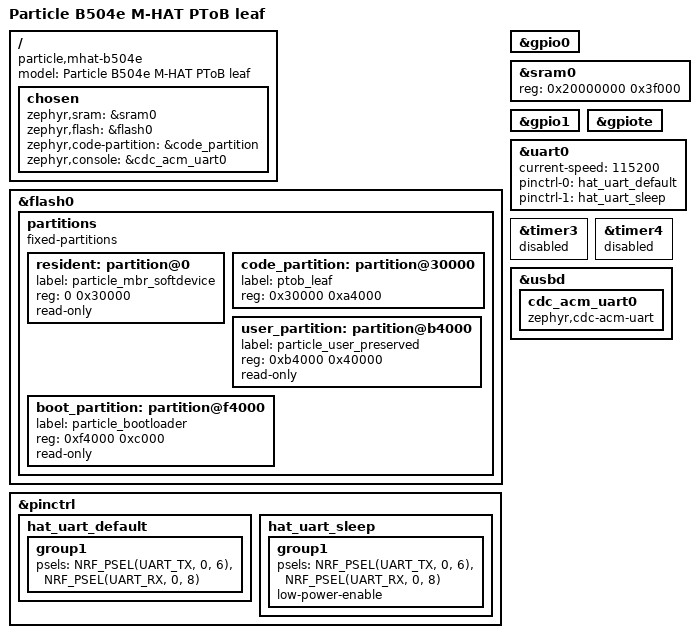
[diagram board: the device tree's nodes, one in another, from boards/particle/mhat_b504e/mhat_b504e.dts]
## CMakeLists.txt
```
# Copyright (c) 2026 Jonathan Yantis. SPDX-License-Identifier: MIT
cmake_minimum_required(VERSION 3.20.0)
list(APPEND BOARD_ROOT ${CMAKE_CURRENT_SOURCE_DIR})
find_package(Zephyr REQUIRED HINTS $ENV{ZEPHYR_BASE})
project(ptob_mhat VERSION 0.5.5)
zephyr_linker_sources(ROM_START SORT_KEY zzz ${CMAKE_CURRENT_SOURCE_DIR}/module_reserve.ld)
set(T096 ${CMAKE_CURRENT_SOURCE_DIR}/../t096)
if(NOT EXISTS "${MHAT_PRIVATE_HEADER}")
 message(FATAL_ERROR "Use tools/build.py with private exact-device enrollment")
endif()
configure_file(${MHAT_PRIVATE_HEADER} ${CMAKE_CURRENT_BINARY_DIR}/mhat_private.h COPYONLY)
target_include_directories(app PRIVATE ${CMAKE_CURRENT_SOURCE_DIR}/include ${CMAKE_CURRENT_BINARY_DIR} ${T096}/include ${T096}/protocol
 ${ZEPHYR_BASE}/subsys/bluetooth/controller/ll_sw/nordic/hal/nrf5/radio)
target_compile_definitions(app PRIVATE R2_RC_PROFILE=1 R2_SWITCHABLE_FIELD=1 R2_TZ_WIRE=1
 R2_USB_SOURCE_STREAM=1 R2_NATIVE_BLE=1)
set_source_files_properties(${T096}/src/rc_dynamic_service.c PROPERTIES COMPILE_DEFINITIONS "R2_DYNAMIC_BACKEND=1;R2_RC_DYNAMIC=1")
target_sources(app PRIVATE src/main.c src/mesh.c src/clock_adapter.c src/pps.c src/support.c src/gm_control.c
 ${T096}/src/core.c ${T096}/src/rc_dynamic_service.c ${T096}/src/rc_boundary.c ${T096}/src/rc_slots.c
 ${T096}/src/rc_unicast.c ${T096}/src/radio_capture.c ${T096}/src/radio_audit.c
 ${T096}/src/initiator_diag.c ${T096}/src/timing_events.c
 ${T096}/protocol/rc_dynamic.c ${T096}/protocol/unicast_time.c ${T096}/protocol/relay_codec.c
 ${T096}/protocol/precision_codec.c ${T096}/protocol/group_join.c ${T096}/protocol/group_auth.c
 ${T096}/protocol/group_control.c ${T096}/protocol/group_precision.c
 ${T096}/protocol/role_announcement.c ${T096}/protocol/gm7_codec.c)
# Reuse pinned controller fixes and capture hooks without editing their sources.
include(${T096}/cmake/clock_handoff.cmake)
set(R2_PC_PROFILE ON) # ticker generator only: this target has no T096 crash storage.
include(${T096}/cmake/ticker_backport.cmake)
unset(R2_PC_PROFILE)
include(${T096}/cmake/radio_capture.cmake)
include(${T096}/cmake/precision_schedule.cmake)
include(${T096}/cmake/controller-radio-fixes.cmake)
include(${T096}/cmake/scan-aux-context.cmake)
target_compile_options(app PRIVATE -Wall -Wextra -Werror -Wno-unused-parameter)
```

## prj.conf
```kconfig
CONFIG_BT=y
CONFIG_BT_LL_SW_SPLIT=y
CONFIG_BT_CENTRAL=y
CONFIG_BT_PERIPHERAL=y
CONFIG_BT_OBSERVER=y
CONFIG_BT_SMP=n
CONFIG_BT_SETTINGS=n
CONFIG_BT_MAX_CONN=4
CONFIG_BT_MAX_PAIRED=0
CONFIG_BT_GATT_CLIENT=y
CONFIG_BT_DEVICE_NAME="PToB M-HAT leaf"
CONFIG_BT_CTLR_PHY_2M=n
CONFIG_BT_CTLR_PHY_CODED=n
CONFIG_BT_CTLR_DF=n
CONFIG_CLOCK_CONTROL_NRF_K32SRC_RC=y
CONFIG_CLOCK_CONTROL_NRF_K32SRC_500PPM=y
CONFIG_CLOCK_CONTROL_NRF_K32SRC_RC_CALIBRATION=y
CONFIG_USB_DEVICE_STACK=y
CONFIG_USB_DEVICE_PRODUCT="PToB M-HAT leaf"
CONFIG_USB_DEVICE_MANUFACTURER="PToB experimental"
CONFIG_USB_CDC_ACM=y
CONFIG_UART_INTERRUPT_DRIVEN=y
CONFIG_UART_LINE_CTRL=y
CONFIG_CONSOLE=n
CONFIG_UART_CONSOLE=n
CONFIG_STDOUT_CONSOLE=n
CONFIG_SHELL=n
CONFIG_LOG=n
CONFIG_PRINTK=n
CONFIG_BOOT_BANNER=n
CONFIG_MAIN_STACK_SIZE=8192
CONFIG_MAIN_THREAD_PRIORITY=10
CONFIG_SYSTEM_WORKQUEUE_STACK_SIZE=5120
CONFIG_SYSTEM_WORKQUEUE_PRIORITY=-1
CONFIG_BT_RX_STACK_SIZE=2048
CONFIG_BT_HCI_TX_STACK_SIZE=1024
CONFIG_HEAP_MEM_POOL_SIZE=0
CONFIG_ASSERT=y
CONFIG_INIT_STACKS=y
CONFIG_THREAD_STACK_INFO=y
CONFIG_THREAD_NAME=y
CONFIG_HWINFO=y
CONFIG_ENTROPY_GENERATOR=y
CONFIG_REBOOT=y
CONFIG_NRFX_TIMER3=y
CONFIG_NRFX_PPI=y
CONFIG_BT_L2CAP_TX_MTU=226
CONFIG_BT_BUF_ACL_RX_SIZE=230
CONFIG_BT_BUF_ACL_TX_SIZE=230
CONFIG_BT_BUF_ACL_TX_COUNT=12
CONFIG_BT_CONN_TX_MAX=12
CONFIG_BT_ATT_TX_COUNT=12
CONFIG_BT_CREATE_CONN_TIMEOUT=2
CONFIG_BT_CTLR_DATA_LENGTH_MAX=230
CONFIG_BT_USER_DATA_LEN_UPDATE=y
CONFIG_BT_BUF_EVT_RX_COUNT=20
CONFIG_BT_CTLR_RX_BUFFERS=8
CONFIG_BT_CTLR_LOW_LAT=n
CONFIG_BT_CTLR_ASSERT_OVERHEAD_START=n
CONFIG_BT_CTLR_ADVANCED_FEATURES=y
CONFIG_BT_GAP_AUTO_UPDATE_CONN_PARAMS=n
CONFIG_BT_AUTO_DATA_LEN_UPDATE=y
CONFIG_BT_EXT_ADV=y
CONFIG_BT_EXT_ADV_MAX_ADV_SET=2
CONFIG_BT_PER_ADV=y
CONFIG_BT_CTLR_ADV_SYNC_SET=2
CONFIG_BT_PER_ADV_SYNC=y
CONFIG_BT_PER_ADV_SYNC_MAX=1
CONFIG_BT_PER_ADV_SYNC_BUF_SIZE=191
CONFIG_BT_CTLR_ADV_DATA_CHAIN=n
CONFIG_BT_CTLR_ADV_DATA_LEN_MAX=191
CONFIG_BT_CTLR_SCAN_DATA_LEN_MAX=191
CONFIG_BT_BUF_EVT_RX_SIZE=255
CONFIG_BT_CTLR_SCAN_AUX_SYNC_RESERVE_MIN=n
CONFIG_BT_TICKER_EXT_EXPIRE_INFO=y
CONFIG_BT_TICKER_PRIORITY_SET=y
CONFIG_TINYCRYPT=y
CONFIG_TINYCRYPT_SHA256=y
CONFIG_TINYCRYPT_SHA256_HMAC=y
CONFIG_BUILD_OUTPUT_BIN=y
CONFIG_BUILD_OUTPUT_HEX=y
CONFIG_STACK_USAGE=y
# Keep module-info at vector+0x200 out of the vector/text region.
CONFIG_ROM_START_OFFSET=0
```

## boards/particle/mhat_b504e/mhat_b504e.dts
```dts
// Copyright (c) 2026 Jonathan Yantis. SPDX-License-Identifier: MIT
/dts-v1/;
#include <nordic/nrf52840_qiaa.dtsi>
#include <zephyr/dt-bindings/gpio/gpio.h>
#include <zephyr/dt-bindings/pinctrl/nrf-pinctrl.h>
/ {
    model = "Particle B504e M-HAT PToB leaf";
    compatible = "particle,mhat-b504e";
    chosen {
        zephyr,sram = &sram0;
        zephyr,flash = &flash0;
        zephyr,code-partition = &code_partition;
        zephyr,console = &cdc_acm_uart0;
    };
};
&flash0 {
    partitions {
        compatible = "fixed-partitions";
        #address-cells = <1>;
        #size-cells = <1>;
        resident: partition@0 { label = "particle_mbr_softdevice"; reg = <0 0x30000>; read-only; };
        code_partition: partition@30000 { label = "ptob_leaf"; reg = <0x30000 0xa4000>; };
        user_partition: partition@b4000 { label = "particle_user_preserved"; reg = <0xb4000 0x40000>; read-only; };
        boot_partition: partition@f4000 { label = "particle_bootloader"; reg = <0xf4000 0xc000>; read-only; };
    };
};
&gpio0 { status = "okay"; };
/* Particle's bootloader owns retained flags/registers in the top 4 KiB. */
&sram0 { reg = <0x20000000 0x3f000>; };
&gpio1 { status = "okay"; };
&gpiote { status = "okay"; };
&pinctrl {
    hat_uart_default: hat_uart_default {
        group1 { psels = <NRF_PSEL(UART_TX, 0, 6)>, <NRF_PSEL(UART_RX, 0, 8)>; };
    };
    hat_uart_sleep: hat_uart_sleep {
        group1 { psels = <NRF_PSEL(UART_TX, 0, 6)>, <NRF_PSEL(UART_RX, 0, 8)>; low-power-enable; };
    };
};
&uart0 {
    status = "okay";
    current-speed = <115200>;
    pinctrl-0 = <&hat_uart_default>;
    pinctrl-1 = <&hat_uart_sleep>;
    pinctrl-names = "default", "sleep";
    /* No RTS/CTS: D2/P1.02 is dedicated to PPS. */
};
&timer3 { status = "disabled"; };
&timer4 { status = "disabled"; };
&usbd {
    status = "okay";
    cdc_acm_uart0: cdc_acm_uart0 { compatible = "zephyr,cdc-acm-uart"; };
};
```

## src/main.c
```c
/* Copyright (c) 2026 Jonathan Yantis. SPDX-License-Identifier: MIT */
#include "mhat_private.h"
#include "ble_service.h"
#include "rc_dynamic_service.h"
#include "capture.h"
#include "radio_capture.h"
#include "usb_source.h"
#include "timing_events.h"
#include <zephyr/bluetooth/bluetooth.h>
#include <zephyr/drivers/hwinfo.h>
#include <zephyr/drivers/uart.h>
#include <zephyr/random/random.h>
#include <zephyr/usb/usb_device.h>
#include <zephyr/sys/reboot.h>
#include <hal/nrf_gpio.h>
#include <hal/nrf_wdt.h>
#include <hal/nrf_power.h>
#include <stdio.h>
#include <stdlib.h>
#include <string.h>
int mhat_clock_start(uint64_t);
int mhat_pps_init(void);
void mhat_pps_poll(void);
void mhat_pps_stats(uint32_t[4]);
void mhat_pps_debug(uint32_t[5]);
int mhat_mesh_start(const struct r2_identity *);
int mhat_mesh_poll(void);
void mhat_mesh_stop(void);
bool mhat_mesh_quiescent(void);
void mhat_mesh_stats(uint32_t[6]);
int mhat_mesh_json(char *,size_t);
static const struct device *console=DEVICE_DT_GET(DT_CHOSEN(zephyr_console));
static const struct device *bus=DEVICE_DT_GET(DT_NODELABEL(uart0));
static char bus_output[8192];
static size_t bus_size,bus_at;
static atomic_t bus_busy;
static int bus_error;
static bool dfu_requested;
static int dfu_status;
static int64_t dfu_deadline;
static void bus_irq(const struct device *dev,void *unused){
    (void)unused;
    if(!uart_irq_update(dev)||!uart_irq_tx_ready(dev))return;
    int n=uart_fifo_fill(dev,(const uint8_t *)bus_output+bus_at,bus_size-bus_at);
    if(n>0)bus_at+=(size_t)n;
    if(bus_at==bus_size){uart_irq_tx_disable(dev);atomic_clear(&bus_busy);}
}
static void line(const char *s){
    /* The header UART drains in interrupts. Telemetry never waits for a host
     * or holds up the PPS planner while a complete line crosses 115200 baud. */
    size_t size=strlen(s);
    if(!bus_error&&size<sizeof bus_output&&atomic_cas(&bus_busy,0,1)){
        memcpy(bus_output,s,size);bus_at=0;bus_size=size;uart_irq_tx_enable(bus);
    }
    uint32_t dtr=0;if(!device_is_ready(console)||uart_line_ctrl_get(console,UART_LINE_CTRL_DTR,&dtr)||!dtr)return;
    for(;*s;s++)uart_poll_out(console,*s);
}
static bool array(char *out,size_t cap,size_t *at,const char *name,const uint32_t *values,size_t count){
    int n=snprintf(out+*at,cap-*at,",\"%s\":[",name);
    if(n<0||(size_t)n>=cap-*at)return false;
    *at+=(size_t)n;
    for(size_t i=0;i<count;i++){
        n=snprintf(out+*at,cap-*at,"%s%u",i?",":"",values[i]);
        if(n<0||(size_t)n>=cap-*at)return false;
        *at+=(size_t)n;
    }
    if(*at+2>=cap)return false;
    out[(*at)++]=']';out[*at]=0;return true;
}
static void watchdog(void){for(unsigned i=0;i<8;i++)if(NRF_WDT->RREN&(1u<<i))NRF_WDT->RR[i]=0x6e524635;}
static void commands(uint64_t boot){
    static char input[180];static size_t at;static bool overflow;
    unsigned char c;
    /* USB possession is the control boundary. No UART or BLE command handler.
     * Every request binds exact factory ID, full installed source and boot. */
    for(unsigned i=0;i<256&&!uart_poll_in(console,&c);i++){
        if(c=='\r')continue;
        if(c!='\n'){if(at+1<sizeof input)input[at++]=(char)c;else overflow=true;continue;}
        input[at]=0;char expected[180];
        snprintf(expected,sizeof expected,"dfu %s %s %016llx",MHAT_PARTICLE_ID,MHAT_SOURCE_SHA,(unsigned long long)boot);
        if(!overflow&&!strcmp(input,expected)&&!dfu_requested){
            dfu_requested=true;dfu_status=1;dfu_deadline=k_uptime_get()+3000;
            mhat_mesh_stop();
        }
        at=0;overflow=false;
    }
    if(dfu_status==1){
        if(mhat_mesh_quiescent()){
            r2_usb_source_withdraw();(void)r2_capture_stop();
            /* Device OS 5.8.2 platform_ram.ld: BKP_DR_01 at 0x2003f380.
             * bootloader main.c consumes ENTER_DFU_APP_REQUEST (0xEDFA).
             * Retained RAM only: no UICR, flash, PMIC or protection change. */
            *(volatile uint32_t *)0x2003f380u=0xedfau;
            __DSB();sys_reboot(SYS_REBOOT_COLD);
        }else if(k_uptime_get()>dfu_deadline)dfu_status=-ETIMEDOUT;
    }
}
int main(void){
    /* Binding uses Particle's USB ID -> exact FICR words; no alias selects HW. */
    if(NRF_FICR->DEVICEID[0]!=MHAT_FICR0||NRF_FICR->DEVICEID[1]!=MHAT_FICR1)return -EACCES;
    /* Pi power pins D8/P1.03, A3/P0.29 and PMIC are never configured here. */
    nrf_gpio_cfg_output(34);nrf_gpio_pin_clear(34); /* PPS low before bus connect */
    nrf_gpio_cfg_output(3);nrf_gpio_pin_set(3); /* A0/SEL: connect UART/PPS switch */
    bus_error=device_is_ready(bus)?uart_irq_callback_user_data_set(bus,bus_irq,NULL):-ENODEV;
    if(!bus_error){uart_irq_rx_disable(bus);uart_irq_tx_disable(bus);}
    if(!NRF_WDT->RUNSTATUS){NRF_WDT->CONFIG=1;NRF_WDT->CRV=5*32768;NRF_WDT->RREN=1;NRF_WDT->TASKS_START=1;}
    struct r2_identity id={.battery=-1};
    uint8_t hw[8];if(hwinfo_get_device_id(hw,sizeof hw)!=sizeof hw)return -ENODEV;
    for(unsigned i=0;i<8;i++)snprintf(id.silicon+2*i,3,"%02x",hw[i]);
    strcpy(id.unit,"MHAT1");sys_rand_get(&id.boot,sizeof id.boot);if(!id.boot)id.boot=1;
    bt_addr_le_t address={.type=BT_ADDR_LE_RANDOM};sys_rand_get(address.a.val,6);address.a.val[5]|=0xc0;
    int rc=bt_id_create(&address,NULL);
    if(rc==0)rc=mhat_clock_start((uint32_t)id.boot?(uint32_t)id.boot:1);
    if(!rc)rc=mhat_pps_init();
    if(!rc)rc=bt_enable(NULL);
    (void)usb_enable(NULL);
    if(!rc)rc=mhat_mesh_start(&id);
    static char output[8192];uint64_t next=0;static struct r2_service_status status;
    static uint64_t source_root,source_parent,source_boot,source_seen;
    static uint32_t source_epoch;
    for(;;){
        watchdog();r2_capture_poll(k_ticks_to_us_floor64(k_uptime_ticks()));
        if(!rc){rc=mhat_mesh_poll();if(!dfu_requested)mhat_pps_poll();}
        if(device_is_ready(console))commands(id.boot);
        uint64_t now=k_uptime_get();
        if(now>=next){
            memset(&status,0,sizeof status);r2_dynamic_service_snapshot(&status);uint32_t pps[4];mhat_pps_stats(pps);
            r2_timing_sample(&status,now);
            int n=snprintf(output,sizeof output,"{\"target\":\"mhat-b504e\",\"version\":\"0.5.5\",\"source\":\"%s\",\"device_id\":\"%s\",\"particle_id\":\"%s\",\"boot\":\"%016llx\",\"uptime_ms\":%llu,\"error\":%d,\"receiver_error\":%d,\"capture_error\":%d,\"uart_error\":%d,\"dfu_status\":%d,\"cycles\":%u,\"active\":%s,\"rx\":%u,\"authenticated\":%u,\"rejected\":%u,\"following\":%s,\"clock_valid\":%s,\"pps_emitted\":%u,\"pps_rejected\":%u,\"pps_armed\":%u,\"offer_valid\":%u,\"pps_pin\":\"P1.02\",\"pi_gpio\":16,\"utc_accuracy_qualified\":false",MHAT_SOURCE_SHA,id.silicon,MHAT_PARTICLE_ID,(unsigned long long)id.boot,(unsigned long long)now,rc,status.error,r2_capture_error(),bus_error,dfu_status,status.cycles,status.active?"true":"false",status.rx,status.authenticated,status.rejected,status.follower?"true":"false",status.follower_clock_valid?"true":"false",pps[0],pps[1],pps[2],pps[3]);
            uint32_t transport[13],acquisition[20],admission[7],connection[20],mesh[6],plan[5];mhat_mesh_stats(mesh);mhat_pps_debug(plan);
            r2_dynamic_service_transport_snapshot(transport);r2_dynamic_service_acquisition_snapshot(acquisition);
            r2_dynamic_service_gm_admission_snapshot(admission);r2_dynamic_service_connection_snapshot(connection);
            struct r2_radio_capture_stats radio;r2_radio_capture_stats(&radio);
            uint32_t captures[]={radio.completed,radio.aborted,radio.invalid,radio.overflow,
                radio.rx.armed,radio.rx.completed,radio.rx.aborted,radio.rx.no_done,radio.rx.no_address,radio.rx.bad_crc};
            size_t at=n>0?(size_t)n:sizeof output;
            if(at<sizeof output&&array(output,sizeof output,&at,"transport",transport,13)&&
                array(output,sizeof output,&at,"acquisition",acquisition,20)&&
                array(output,sizeof output,&at,"admission",admission,7)&&
                array(output,sizeof output,&at,"connection",connection,20)&&
                array(output,sizeof output,&at,"mesh",mesh,6)&&
                array(output,sizeof output,&at,"radio",captures,10)&&
                array(output,sizeof output,&at,"pps_plan",plan,5)){
                n=snprintf(output+at,sizeof output-at,
                    ",\"path\":[\"%016llx\",\"%016llx\",\"%016llx\",\"%016llx\"],"
                    "\"fit\":{\"locked\":%s,\"samples\":%u,\"rms_valid\":%s,\"rms_ns\":%u,"
                    "\"drift_valid\":%s,\"drift_ppb\":%d,\"age_valid\":%s,\"age_ms\":%u}",
                    (unsigned long long)status.identities[0],(unsigned long long)status.identities[1],
                    (unsigned long long)status.identities[2],(unsigned long long)status.identities[3],
                    status.precision.locked?"true":"false",status.precision.samples,
                    status.precision.rms_valid?"true":"false",status.precision.rms_ns,
                    status.precision.drift_valid?"true":"false",status.precision.drift_ppb,
                    status.precision.correction_age_valid?"true":"false",status.precision.correction_age_ms);
                if(n>0&&(size_t)n<sizeof output-at){
                    at+=(size_t)n;
                    if(status.follower_clock_valid&&status.relay.root_identity){
                        source_root=status.relay.root_identity;source_parent=status.relay.parent_identity;
                        source_boot=status.root_boot;source_epoch=status.source_epoch;source_seen=now;
                    }
                    n=snprintf(output+at,sizeof output-at,",\"clock_source\":{\"valid\":%s,"
                        "\"root\":\"%016llx\",\"parent\":\"%016llx\",\"root_boot\":\"%016llx\","
                        "\"epoch\":%u,\"last_valid_ms\":%llu}",status.follower_clock_valid?"true":"false",
                        (unsigned long long)source_root,(unsigned long long)source_parent,
                        (unsigned long long)source_boot,source_epoch,(unsigned long long)source_seen);
                    if(n<0||(size_t)n>=sizeof output-at)goto sample_done;
                    at+=(size_t)n;n=mhat_mesh_json(output+at,sizeof output-at);
                    if(n<0)goto sample_done;
                    at+=(size_t)n;static char event[768];static uint32_t cursor;
                    int count=r2_timing_json(event,sizeof event,id.boot,cursor);
                    if(count>0&&at+(size_t)count+24<sizeof output){
                        n=snprintf(output+at,sizeof output-at,",\"timing_event\":%s",event);at+=(size_t)n;
                        char *sequence=strstr(event,"\"sequence\":");
                        if(sequence){uint32_t seq=(uint32_t)strtoul(sequence+11,NULL,10);if(seq>cursor)cursor=seq;}
                    }
                    if(at+4<sizeof output){memcpy(output+at,"}\r\n",4);line(output);}
                }
            }
sample_done:next=now+1000;
        }
        k_sleep(K_MSEC(5));
    }
}
```

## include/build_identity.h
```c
/* Copyright (c) 2026 Jonathan Yantis. MIT. */
#pragma once
#include "mhat_private.h"
#define R2_SOURCE_SHA MHAT_SOURCE_SHA
```

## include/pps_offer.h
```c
/* Copyright (c) 2026 Jonathan Yantis. MIT. Semantic immutable-offer identity. */
#pragma once
#include "rc_unicast.h"
#include <string.h>
static inline bool mhat_pps_revision_current(uint32_t snapshot,uint32_t current){
 /* Saturation is a permanent withdrawal fence, never a valid ABA revision. */
 return snapshot!=UINT32_MAX&&snapshot==current;
}
static inline bool mhat_pps_offer_same(const struct r2_uc_clock *a,const struct r2_uc_clock *b){
 /* Never compare C padding: identical owner polls must not invalidate planning.
  * Include authority/expiry as well as phase; a lease change is not a no-op. */
#define SAME(member) (a->member==b->member)
 return SAME(valid)&&SAME(estimate)&&SAME(capture_epoch)&&SAME(depth)&&
  SAME(until_tick)&&SAME(session_until)&&SAME(discipline_tick)&&!memcmp(a->scope,b->scope,16)&&
  SAME(map.effective)&&SAME(map.anchor_tick)&&SAME(map.anchor_ns)&&SAME(map.ppb)&&
  SAME(map.phase_ns)&&SAME(map.generation)&&SAME(map.age_us)&&SAME(map.bound)&&
  SAME(map.rate_bound)&&SAME(map.capture_bound)&&SAME(map.continuous)&&
  SAME(origin.root)&&SAME(origin.boot)&&SAME(origin.epoch)&&SAME(origin.issued)&&
  SAME(origin.expires)&&SAME(origin.utc_offset)&&SAME(origin.frame)&&
  SAME(origin.hold_us)&&SAME(origin.hold_ns);
#undef SAME
}
```

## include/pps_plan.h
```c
/* Copyright (c) 2026 Jonathan Yantis. MIT. Pure checked PPS planner. */
#pragma once
#include "rc_unicast.h"
#include <limits.h>
/* Re-project the latest admitted map until the edge is near. */
#define MHAT_PPS_ARM_MAX_TICKS UINT64_C(320000) /* 20 ms at 16 MHz */
static inline bool mhat_pps_commit_ready(uint64_t now,uint64_t edge) {
    return edge>now && edge-now>=48000 && edge-now<=MHAT_PPS_ARM_MAX_TICKS;
}
static inline bool mhat_utc_at(const struct r2_uc_clock *o,uint64_t tick,uint64_t *utc) {
    uint64_t ns,elapsed;
    if(!o->valid||tick>=o->until_tick||tick>=o->session_until||tick<o->map.effective||
       !rc5_map_project(&o->map,tick,&ns,&elapsed)||ns<o->origin.issued||ns>=o->origin.expires)return false;
    if(o->origin.utc_offset<0){uint64_t mag=(uint64_t)(-(o->origin.utc_offset+1))+1;if(ns<mag)return false;*utc=ns-mag;}
    else {if(ns>UINT64_MAX-(uint64_t)o->origin.utc_offset)return false;*utc=ns+(uint64_t)o->origin.utc_offset;}
    return true;
}
static inline bool mhat_pps_plan(const struct r2_uc_clock *o,uint64_t now,uint64_t last,uint64_t *edge,uint64_t *second) {
    uint64_t utc,value;
    if(now>UINT64_MAX-UINT64_C(16000000)||!mhat_utc_at(o,now,&utc))return false;
    uint64_t s=utc/1000000000+1;
    if(s<=last||s>UINT64_MAX/1000000000)return false;
    uint64_t target=s*UINT64_C(1000000000),lo=now,hi=now+UINT64_C(16000000);
    if(hi>=o->until_tick)hi=o->until_tick-1;
    if(hi>=o->session_until)hi=o->session_until-1;
    if(hi<=lo)return false;
    /* The source's projected expiry can precede the local/session deadline.
     * An invalid far endpoint does not make an earlier pulse invalid. Search
     * for the target OR the first invalid tick, then require a valid crossing
     * and the complete pulse below. This never extends any permission. */
    while(hi-lo>1){uint64_t mid=lo+(hi-lo)/2;
        if(!mhat_utc_at(o,mid,&value)||value>=target)hi=mid;else lo=mid;}
    /* Nearest attainable edge, rather than always rounding late. Fractional
     * phase remains in the disciplined map; output alone is quantized. */
    uint64_t lower,upper;
    if(!mhat_utc_at(o,lo,&lower)||!mhat_utc_at(o,hi,&upper)||lower>target||upper<target)return false;
    if(target-lower<upper-target)hi=lo;
    if(hi-now<48000||hi>UINT64_MAX-160000||!mhat_utc_at(o,hi+160000,&value))return false;
    *edge=hi;*second=s;return true;
}
```

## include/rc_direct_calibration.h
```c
/* Copyright (c) 2026 Jonathan Yantis. MIT.
 * This board has no independently measured receive phase calibration.
 * Do not import T096's empirical board/run-specific phase correction.
 */
#pragma once
#define RC_DIRECT_PPS_CORRECTION_NS 0
```

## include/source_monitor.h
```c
/* Copyright 2026 Jonathan Yantis. SPDX-License-Identifier: MIT */
#pragma once
#include "role_announcement.h"
#include "rc_search.h"
#include "rc_stream_quality.h"
#include <string.h>
/* The native owner must finish its bounded search and longest parent trial.
 * This outer cap never extends a source/map/admission/output permission. */
#define MHAT_CONTEXT_RECOVERY_MS ((RC_SEARCH_LIMIT_US+RC_STREAM_TRIAL_US)/1000+30000)
#define MHAT_ROLE_ROWS 8u
struct mhat_role_row {
    struct r2_role_record report;
    uint64_t group, received_us;
};
struct mhat_role_monitor {
    struct mhat_role_row row[MHAT_ROLE_ROWS];
    uint32_t accepted, replayed, expired, capacity_refused;
};
/* Authenticated descriptive reports only; never an input to mesh selection,
 * PPS permission or timing. Keep per-incarnation replay fences across epochs. */
static inline bool mhat_role_observe(struct mhat_role_monitor *m,uint64_t group,
        const struct r2_role_record *r,uint64_t at,uint64_t now){
    if(!group||!r->root||!r->root_boot||!r->sequence||!r->valid_us||
       r->valid_us>R2_ROLE_MAX_VALID_US||now<at||now-at>=r->valid_us){
        ++m->expired;return false;
    }
    unsigned slot=MHAT_ROLE_ROWS;bool found=false;
    for(unsigned i=0;i<MHAT_ROLE_ROWS;i++){
        const struct mhat_role_row *p=&m->row[i];
        if(p->group==group&&p->report.root==r->root&&p->report.root_boot==r->root_boot){
            slot=i;found=true;break;
        }
        if(!p->group&&slot==MHAT_ROLE_ROWS)slot=i;
    }
    /* Never evict a replay fence. A full diagnostic cache refuses unseen
     * incarnations until reboot; normal timing admission remains independent. */
    if(!found&&slot==MHAT_ROLE_ROWS){++m->capacity_refused;return false;}
    struct mhat_role_row *p=&m->row[slot];
    if(found&&(r->sequence<=p->report.sequence||r->created_us<p->report.created_us)){
        ++m->replayed;return false;
    }
    *p=(struct mhat_role_row){.group=group,.received_us=at,.report=*r};
    ++m->accepted;return true;
}
```

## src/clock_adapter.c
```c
/* Copyright (c) 2026 Jonathan Yantis. SPDX-License-Identifier: MIT */
#include "capture.h"
#include "radio_capture.h"
#include <errno.h>
#include <nrfx_timer.h>
#include <nrfx_ppi.h>
#include <hal/nrf_radio.h>
#include <zephyr/drivers/clock_control/nrf_clock_control.h>
#include <zephyr/sys/onoff.h>
static const nrfx_timer_t timer = NRFX_TIMER_INSTANCE(3);
static struct onoff_client client;
static struct k_spinlock lock;
static nrf_ppi_channel_t route;
static uint64_t ticks, epoch;
static uint32_t raw;
static int64_t last_us;
static int fault;
static bool running;
int mhat_clock_start(uint64_t incarnation) {
    struct onoff_manager *manager=z_nrf_clock_control_get_onoff(CLOCK_CONTROL_NRF_SUBSYS_HF);
    sys_notify_init_spinwait(&client.notify);
    if(onoff_request(manager,&client)<0)return -EIO;
    int result=-EAGAIN;
    for(unsigned i=0;i<25;i++) {
        if(!sys_notify_fetch_result(&client.notify,&result))break;
        k_sleep(K_MSEC(1));
    }
    if(result)return result;
    nrfx_timer_config_t config=NRFX_TIMER_DEFAULT_CONFIG(16000000);
    config.bit_width=NRF_TIMER_BIT_WIDTH_32;
    if(nrfx_timer_init(&timer,&config,NULL)!=NRFX_SUCCESS)return -EIO;
    if(nrfx_ppi_channel_alloc(&route)!=NRFX_SUCCESS)return -ENOMEM;
    if(nrfx_ppi_channel_assign(route,nrf_radio_event_address_get(NRF_RADIO,NRF_RADIO_EVENT_ADDRESS),
                              nrfx_timer_capture_task_address_get(&timer,1))!=NRFX_SUCCESS)return -EIO;
    nrfx_timer_enable(&timer);
    epoch=incarnation;raw=nrfx_timer_capture(&timer,2);ticks=raw;
    last_us=k_ticks_to_us_floor64(k_uptime_ticks());running=true;
    return r2_radio_capture_enable((uint32_t)epoch,route);
}
static bool current(struct r2_capture *out,uint64_t *mono) {
    k_spinlock_key_t key=k_spin_lock(&lock);
    int64_t at=k_ticks_to_us_floor64(k_uptime_ticks());
    uint32_t n=nrfx_timer_capture(&timer,2),delta=n-raw;
    if(!running||fault||at<last_us||at-last_us>1000000||delta>=0x80000000u)fault=-ESTALE;
    if(!fault){ticks+=delta;raw=n;last_us=at;*out=(struct r2_capture){ticks,epoch,R2_CAPTURE_NOW};if(mono)*mono=at;}
    k_spin_unlock(&lock,key);return !fault;
}
bool r2_capture_now(struct r2_capture *out){return current(out,NULL);}
bool r2_capture_now_at(struct r2_capture *out,uint64_t *at){return current(out,at);}
bool r2_capture_radio(uint32_t value,uint32_t e,struct r2_capture *out){
    struct r2_capture n;if(!current(&n,NULL)||e!=(uint32_t)n.epoch)return false;
    uint32_t age=(uint32_t)n.tick-value;
    if(age>16000000||n.tick<age)return false;
    *out=(struct r2_capture){n.tick-age,n.epoch,R2_CAPTURE_RADIO};return true;
}
void r2_capture_poll(int64_t now){struct r2_capture n;(void)now;(void)current(&n,NULL);}
int r2_capture_error(void){return fault;}
int r2_capture_stop(void){running=false;return r2_radio_capture_disable();}
```

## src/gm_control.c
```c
/* Copyright 2026 Jonathan Yantis. SPDX-License-Identifier: MIT
 * Reciprocal GM admission return path. The shared RC owner owns the exact
 * connection, wire length, authenticated exchange and original deadlines.
 */
#include "ble_service.h"
#include <zephyr/bluetooth/gatt.h>
static struct bt_uuid_128 service_uuid=BT_UUID_INIT_128(
    BT_UUID_128_ENCODE(0x850d0400,0xa6ef,0x4775,0x974b,0x188a7d4ed45c));
static struct bt_uuid_128 data_uuid=BT_UUID_INIT_128(
    BT_UUID_128_ENCODE(0x850d0401,0xa6ef,0x4775,0x974b,0x188a7d4ed45c));
static const uint8_t marker[]={'R','2','G','1',1};
static ssize_t read_marker(struct bt_conn *conn,const struct bt_gatt_attr *attr,
        void *buf,uint16_t len,uint16_t offset){
    return bt_gatt_attr_read(conn,attr,buf,len,offset,marker,sizeof marker);
}
static ssize_t receive(struct bt_conn *conn,const struct bt_gatt_attr *attr,
        const void *buf,uint16_t len,uint16_t offset,uint8_t flags){
    return r2_rc7_gm_receive(conn,buf,len,offset);
}
BT_GATT_SERVICE_DEFINE(mhat_gm_control_service,
    BT_GATT_PRIMARY_SERVICE(&service_uuid),
    BT_GATT_CHARACTERISTIC(&data_uuid.uuid,
        BT_GATT_CHRC_READ|BT_GATT_CHRC_WRITE_WITHOUT_RESP,
        BT_GATT_PERM_READ|BT_GATT_PERM_WRITE,read_marker,receive,NULL));
```

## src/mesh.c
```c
/* Copyright 2026 Jonathan Yantis. SPDX-License-Identifier: MIT
 * A local, unauthenticated G1 hint selects a context to TRY. Only the current
 * RC owner can authenticate it and grant a clock offer. Trust is separate.
 */
#include "mhat_private.h"
#include "ble_service.h"
#include "rc_dynamic_service.h"
#include "rc_admission_policy.h"
#include "usb_source.h"
#include "source_monitor.h"
#include <zephyr/bluetooth/bluetooth.h>
#include <zephyr/kernel.h>
#include <string.h>
#include <stdlib.h>
#include <stdio.h>
enum { IDLE, SCAN, RUNNING, DRAIN };
static unsigned state;
static bool halted;
static atomic_t listening;
static struct k_spinlock hint_lock;
static struct r2_identity identity;
static uint64_t candidate, selected, failed;
static int8_t best_rssi;
static int64_t deadline, retry_at, last_valid, failed_until;
static uint32_t hints, selections, restarts;
static int last_error;
static struct mhat_role_monitor roles;
static struct { uint8_t wire[R2_ROLE_AD_BYTES];uint64_t at; } role_pending;
static bool role_queued;
static uint32_t role_auth_rejected,role_overwritten;
struct observation { bool connectable; int8_t rssi; };
static bool parse(struct bt_data *d,void *opaque){
    const struct observation *o=opaque;
    /* Copy only in the Bluetooth callback. Authentication runs in the main
     * loop, outside radio/controller work; this adds no scan or transmission. */
    if(d->type==BT_DATA_MANUFACTURER_DATA&&d->data_len==R2_ROLE_AD_BYTES-2&&
       d->data[0]==0xff&&d->data[1]==0xff&&d->data[2]=='G'&&d->data[3]=='S'&&
       r2_group_get(d->data+14,4)==MHAT_KEY_EPOCH){
        k_spinlock_key_t key=k_spin_lock(&hint_lock);
        if(role_queued)++role_overwritten;
        role_pending.wire[0]=R2_ROLE_AD_BYTES-1;role_pending.wire[1]=0xff;
        memcpy(role_pending.wire+2,d->data,d->data_len);role_pending.at=k_uptime_get()*1000;
        role_queued=true;k_spin_unlock(&hint_lock,key);return true;
    }
    if(!atomic_get(&listening))return true;
    if(d->type!=BT_DATA_MANUFACTURER_DATA||d->data_len!=23||
       d->data[0]!='G'||d->data[1]!='1'||
       !rc_admission_g1_direct(d->data[2],o->connectable)||
       r2_group_get(d->data+11,4)!=MHAT_KEY_EPOCH)return true;
    uint64_t id=r2_group_get(d->data+3,8);
    if(!id)return false;
    k_spinlock_key_t key=k_spin_lock(&hint_lock);
    ++hints;
    if(!(id==failed&&k_uptime_get()<failed_until)&&(!candidate||o->rssi>best_rssi)){
        candidate=id;best_rssi=o->rssi;
    }
    k_spin_unlock(&hint_lock,key);return false;
}
static void received(const struct bt_le_scan_recv_info *info,struct net_buf_simple *ad){
    struct observation o={.connectable=!!(info->adv_props&BT_GAP_ADV_PROP_CONNECTABLE),.rssi=info->rssi};
    bt_data_parse(ad,parse,&o);
}
static void role_poll(void){
    static uint8_t wire[R2_ROLE_AD_BYTES];uint64_t at=0;
    k_spinlock_key_t key=k_spin_lock(&hint_lock);
    if(role_queued){memcpy(wire,role_pending.wire,sizeof wire);at=role_pending.at;role_queued=false;}
    k_spin_unlock(&hint_lock,key);if(!at)return;
    struct r2_group_config group={.id=r2_group_get(wire+8,8),.epoch=MHAT_KEY_EPOCH,.psk=MHAT_PSK};
    struct r2_role_record r;
    if(r2_role_decode(&r,wire,sizeof wire,&group)){++role_auth_rejected;return;}
    (void)mhat_role_observe(&roles,group.id,&r,at,k_uptime_get()*1000);
}
static struct bt_le_scan_cb callbacks={.recv=received};
int mhat_mesh_start(const struct r2_identity *id){
    identity=*id;bt_le_scan_cb_register(&callbacks);return 0;
}
void mhat_mesh_stop(void){
    halted=true;r2_usb_source_withdraw();
    if(state==SCAN){atomic_clear(&listening);last_error=bt_le_scan_stop();if(!last_error)state=IDLE;}
    if(state==RUNNING){r2_dynamic_service_stop();state=DRAIN;deadline=k_uptime_get()+2500;}
}
bool mhat_mesh_quiescent(void){return state==IDLE;}
int mhat_mesh_poll(void){
    int64_t now=k_uptime_get();
    role_poll();
    static struct r2_service_status s;
    if(state==RUNNING||state==DRAIN){
        r2_dynamic_service_supervise();r2_dynamic_service_snapshot(&s);
        if(state==RUNNING){
            if(s.follower_clock_valid&&!s.error)last_valid=now;
            if((s.closed&&!s.active)||(uint64_t)(now-last_valid)>MHAT_CONTEXT_RECOVERY_MS){
                r2_usb_source_withdraw();r2_dynamic_service_stop();state=DRAIN;deadline=now+2500;
                k_spinlock_key_t key=k_spin_lock(&hint_lock);failed=selected;failed_until=now+20000;k_spin_unlock(&hint_lock,key);
                ++restarts;
            }
        }else if(s.closed&&!s.active){state=IDLE;retry_at=now+1000;}
        else if(now>deadline)return last_error=-ETIMEDOUT;
    }
    if(state==IDLE&&!halted&&now>=retry_at){
        k_spinlock_key_t key=k_spin_lock(&hint_lock);candidate=0;best_rssi=-127;k_spin_unlock(&hint_lock,key);
        struct bt_le_scan_param p={.type=BT_LE_SCAN_TYPE_PASSIVE,.interval=80,.window=40};
        atomic_set(&listening,1);last_error=bt_le_scan_start(&p,NULL);
        if(last_error){atomic_clear(&listening);return last_error;}
        state=SCAN;deadline=now+1500;
    }
    if(state==SCAN&&!halted&&now>=deadline){
        atomic_clear(&listening);last_error=bt_le_scan_stop();if(last_error)return last_error;
        k_spinlock_key_t key=k_spin_lock(&hint_lock);selected=candidate;k_spin_unlock(&hint_lock,key);
        state=IDLE;retry_at=now+1000;
        if(selected){
            struct r2_enrollment e={.group={.id=selected,.epoch=MHAT_KEY_EPOCH,.psk=MHAT_PSK},
                .rc_dynamic=true,.rc7_leaf=true,.rc7_boot_rc=true,.map_bound_us=RC5_UNKNOWN};
            /* Normal G1 admission binds the caller's actual BLE address to its
             * authenticated identity. Derive it from the discovered context;
             * public bt_disable() clears ID0, which bt_id_reset() cannot reset.
             * A previous owner is fully drained before reaching this branch. */
            uint64_t self=strtoull(identity.silicon,NULL,16);uint8_t derived[16];
            r2_group_pair_key(derived,&e.group,self,self);
            bt_addr_le_t own={.type=BT_ADDR_LE_RANDOM};memcpy(own.a.val,derived,6);own.a.val[5]|=0xc0;
            last_error=bt_disable();if(last_error)return last_error;
            last_error=bt_id_create(&own,NULL);if(last_error)return last_error;
            last_error=bt_enable(NULL);if(last_error)return last_error;
            /* configure() clears old context state. run() repeats ordinary
             * JOIN/proof admission; an advertisement cannot authorize PPS. */
            r2_usb_source_withdraw();last_error=r2_dynamic_service_configure(&identity,&e);
            if(!last_error)last_error=r2_dynamic_service_run(now);
            if(last_error)return last_error;
            state=RUNNING;last_valid=now;++selections;
        }
    }
    return 0;
}
void mhat_mesh_stats(uint32_t out[6]){
    k_spinlock_key_t key=k_spin_lock(&hint_lock);
    out[0]=1;out[1]=hints;out[2]=selections;out[3]=restarts;out[4]=state;out[5]=(uint32_t)last_error;
    k_spin_unlock(&hint_lock,key);
}
int mhat_mesh_json(char *out,size_t size){
    uint64_t now=k_uptime_get(),valid_at=(uint64_t)last_valid,age=now>=valid_at?now-valid_at:0;
    int n=snprintf(out,size,",\"discovery\":{\"context\":\"%016llx\",\"state\":%u,"
        "\"no_clock_ms\":%llu,\"restart_after_ms\":%llu,\"role_auth_rejected\":%u,"
        "\"role_replayed\":%u,\"role_overwritten\":%u,\"role_capacity_refused\":%u,\"reports\":[",
        (unsigned long long)selected,state,(unsigned long long)age,
        (unsigned long long)(age<MHAT_CONTEXT_RECOVERY_MS?MHAT_CONTEXT_RECOVERY_MS-age:0),
        role_auth_rejected,roles.replayed,role_overwritten,roles.capacity_refused);
    if(n<0||(size_t)n>=size)return -ENOSPC;
    size_t used=n;unsigned count=0;
    for(unsigned i=0;i<MHAT_ROLE_ROWS;i++){
        const struct mhat_role_row *p=&roles.row[i];const struct r2_role_record *r=&p->report;
        if(!p->group)continue;
        uint64_t age_us=now*1000>=p->received_us?now*1000-p->received_us:UINT64_MAX;
        n=snprintf(out+used,size-used,"%s{\"context\":\"%016llx\",\"root\":\"%016llx\","
            "\"root_boot\":\"%016llx\",\"hot\":\"%016llx\",\"hot_boot\":\"%016llx\","
            "\"epoch\":%u,\"sequence\":%u,\"age_ms\":%llu,\"fresh\":%s}",count?",":"",
            (unsigned long long)p->group,(unsigned long long)r->root,(unsigned long long)r->root_boot,
            (unsigned long long)r->hot,(unsigned long long)r->hot_boot,r->source_epoch,r->sequence,
            (unsigned long long)(age_us/1000),age_us<r->valid_us?"true":"false");
        if(n<0||(size_t)n>=size-used)return -ENOSPC;
        used+=n;++count;
    }
    n=snprintf(out+used,size-used,"]}");
    return n<0||(size_t)n>=size-used?-ENOSPC:(int)(used+n);
}
```

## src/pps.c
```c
/* Copyright (c) 2026 Jonathan Yantis. SPDX-License-Identifier: MIT
 * TIMER3 compares -> PPI -> GPIOTE SET/CLR, with hardware one-shot disable.
 * The immutable RC owner offer retains its original source/session deadlines.
 */
#include "capture.h"
#include "rc_unicast.h"
#include "usb_source.h"
#include "pps_plan.h"
#include "pps_offer.h"
#include <errno.h>
#include <limits.h>
#include <string.h>
#include <zephyr/kernel.h>
#include <nrfx_gpiote.h>
#include <nrfx_ppi.h>
#include <hal/nrf_timer.h>
#include <hal/nrf_gpio.h>
static struct k_spinlock lock;
static struct r2_uc_clock offer;
static nrf_ppi_channel_t rise,fall;
static nrf_ppi_channel_group_t group;
static uint8_t channel;
static bool ready,armed;
static uint64_t scheduled_second,last_second;
static uint32_t emitted,rejected,revision;
static uint32_t last_lead_ns,last_map_age_us,armed_revision,deferred;
static const nrfx_gpiote_t gpiote=NRFX_GPIOTE_INSTANCE(0);
#define PPS_PIN 34u /* P1.02 D2/RTS -> M-HAT -> Pi GPIO16 */
static void disarm(void) {
    if(ready){nrfx_ppi_group_disable(group);nrf_gpiote_task_trigger(NRF_GPIOTE,(nrf_gpiote_task_t)(NRF_GPIOTE_TASK_CLR_0+4*channel));}
    armed=false;
}
int mhat_pps_init(void) {
    if(!nrfx_gpiote_init_check(&gpiote))return -ENODEV;
    if(nrfx_gpiote_channel_alloc(&gpiote,&channel)!=NRFX_SUCCESS||
       nrfx_ppi_channel_alloc(&rise)!=NRFX_SUCCESS||nrfx_ppi_channel_alloc(&fall)!=NRFX_SUCCESS||
       nrfx_ppi_group_alloc(&group)!=NRFX_SUCCESS)return -ENOMEM;
    nrf_gpio_cfg_output(PPS_PIN);nrf_gpio_pin_clear(PPS_PIN);
    nrf_gpiote_task_configure(NRF_GPIOTE,channel,PPS_PIN,NRF_GPIOTE_POLARITY_TOGGLE,NRF_GPIOTE_INITIAL_VALUE_LOW);
    nrf_gpiote_task_enable(NRF_GPIOTE,channel);
    uint32_t set=nrf_gpiote_task_address_get(NRF_GPIOTE,(nrf_gpiote_task_t)(NRF_GPIOTE_TASK_SET_0+4*channel));
    uint32_t clr=nrf_gpiote_task_address_get(NRF_GPIOTE,(nrf_gpiote_task_t)(NRF_GPIOTE_TASK_CLR_0+4*channel));
    if(nrfx_ppi_channel_assign(rise,nrf_timer_event_address_get(NRF_TIMER3,NRF_TIMER_EVENT_COMPARE4),set)!=NRFX_SUCCESS||
       nrfx_ppi_channel_assign(fall,nrf_timer_event_address_get(NRF_TIMER3,NRF_TIMER_EVENT_COMPARE5),clr)!=NRFX_SUCCESS||
       nrfx_ppi_channels_include_in_group((1u<<rise)|(1u<<fall),group)!=NRFX_SUCCESS||
       nrfx_ppi_channel_fork_assign(fall,nrf_ppi_task_address_get(NRF_PPI,nrf_ppi_group_disable_task_get(NRF_PPI,group)))!=NRFX_SUCCESS)return -EIO;
    ready=true;disarm();return 0;
}
void r2_usb_source_withdraw(void){k_spinlock_key_t k=k_spin_lock(&lock);if((offer.valid||armed)&&revision<UINT32_MAX)++revision;offer=(struct r2_uc_clock){0};disarm();k_spin_unlock(&lock,k);}
void r2_usb_source_begin(uint64_t activation,uint64_t epoch){(void)activation;(void)epoch;r2_usb_source_withdraw();}
void r2_usb_source_prepare(uint64_t activation,uint64_t epoch,const struct r2_uc_clock *old){
    if(old&&old->valid&&old->capture_epoch==epoch&&activation<old->until_tick)r2_usb_source_publish(old);
    else r2_usb_source_withdraw();
}
void r2_usb_source_publish(const struct r2_uc_clock *next){
    k_spinlock_key_t k=k_spin_lock(&lock);
    if(!next||!next->valid){
        if((offer.valid||armed)&&revision<UINT32_MAX)++revision;
        offer=(struct r2_uc_clock){0};disarm();
    }else if(!mhat_pps_offer_same(&offer,next)){
        /* Same owner map at routine polling cadence is not a mutation. Fence
         * real changes only, matching the T096 USB publisher's contract. */
        if(revision>=UINT32_MAX-1){revision=UINT32_MAX;offer=(struct r2_uc_clock){0};disarm();}
        else {
            ++revision;
            if(offer.capture_epoch!=next->capture_epoch||memcmp(offer.scope,next->scope,16)||
               offer.origin.root!=next->origin.root||offer.origin.boot!=next->origin.boot||
               offer.origin.epoch!=next->origin.epoch||offer.origin.utc_offset!=next->origin.utc_offset||
               next->until_tick<offer.until_tick||next->session_until<offer.session_until||
               next->origin.expires<offer.origin.expires)disarm();
            offer=*next;
        }
    }
    k_spin_unlock(&lock,k);
}
void mhat_pps_poll(void) {
    if(!ready)return;
    struct r2_capture now;if(!r2_capture_now(&now)){r2_usb_source_withdraw();return;}
    struct r2_uc_clock snapshot;uint32_t rev;uint64_t last;bool pending;
    k_spinlock_key_t k=k_spin_lock(&lock);
    if(armed&&nrf_timer_event_check(NRF_TIMER3,NRF_TIMER_EVENT_COMPARE4)) {
        ++emitted;last_second=scheduled_second;
        nrf_timer_event_clear(NRF_TIMER3,NRF_TIMER_EVENT_COMPARE4);
    }
    if(armed&&nrf_timer_event_check(NRF_TIMER3,NRF_TIMER_EVENT_COMPARE5)) {
        armed=false;nrf_timer_event_clear(NRF_TIMER3,NRF_TIMER_EVENT_COMPARE5);
    }
    snapshot=offer;rev=revision;last=last_second;pending=armed;
    k_spin_unlock(&lock,k);
    uint64_t utc,hi,second;
    if(snapshot.capture_epoch!=now.epoch||!mhat_utc_at(&snapshot,now.tick,&utc)){
        k=k_spin_lock(&lock);if(revision==rev)disarm();k_spin_unlock(&lock,k);return;
    }
    /* Checked projection and binary search run with interrupts enabled. */
    if(!pending&&UINT64_C(1000000000)-utc%UINT64_C(1000000000)>UINT64_C(21000000)){
        ++deferred;return;
    }
    if(pending||!mhat_pps_plan(&snapshot,now.tick,last,&hi,&second))return;
    if(!mhat_pps_commit_ready(now.tick,hi)){++deferred;return;}
    k=k_spin_lock(&lock);
    struct r2_capture after;
    if(!mhat_pps_revision_current(rev,revision)||armed||!r2_capture_now(&after)||after.epoch!=now.epoch||hi<=after.tick+16000){
        ++rejected;k_spin_unlock(&lock,k);return;
    }
    disarm();nrf_timer_event_clear(NRF_TIMER3,NRF_TIMER_EVENT_COMPARE4);nrf_timer_event_clear(NRF_TIMER3,NRF_TIMER_EVENT_COMPARE5);
    nrf_timer_cc_set(NRF_TIMER3,NRF_TIMER_CC_CHANNEL4,(uint32_t)hi);
    nrf_timer_cc_set(NRF_TIMER3,NRF_TIMER_CC_CHANNEL5,(uint32_t)(hi+160000));
    last_lead_ns=(uint32_t)((hi-after.tick)*125/2);
    last_map_age_us=(uint32_t)((after.tick-snapshot.map.effective)/16);
    armed_revision=rev;
    scheduled_second=second;armed=true;nrfx_ppi_group_enable(group);
    k_spin_unlock(&lock,k);
}
void mhat_pps_stats(uint32_t out[4]){k_spinlock_key_t k=k_spin_lock(&lock);out[0]=emitted;out[1]=rejected;out[2]=armed;out[3]=offer.valid;k_spin_unlock(&lock,k);}
void mhat_pps_debug(uint32_t out[5]){k_spinlock_key_t k=k_spin_lock(&lock);out[0]=last_lead_ns;out[1]=last_map_age_us;out[2]=revision;out[3]=armed_revision;out[4]=deferred;k_spin_unlock(&lock,k);}
```

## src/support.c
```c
/* Copyright (c) 2026 Jonathan Yantis. SPDX-License-Identifier: MIT
 * The leaf reuses the current RC owner. These display/observer adapters grant
 * no permission and never substitute for the owner's authenticated clock.
 */
#include "ble_service.h"
#include "rc_dynamic_service.h"
#include "rc_shadow.h"
#include "health.h"
#include "time_service.h"
#include <string.h>
bool r2_switch_rc_active(void){return true;}
void r2_service_stop(void){r2_dynamic_service_stop();}
void r2_service_snapshot(struct r2_service_status *s){r2_dynamic_service_snapshot(s);}
void r2_health_lock_enter(unsigned site,unsigned mask){(void)site;(void)mask;}
void r2_health_lock_leave(unsigned mask){(void)mask;}
void r2_shadow_normal_withdraw(void){}
void r2_shadow_serving(bool enabled){(void)enabled;}
void r2_shadow_poll(void){}
void r2_shadow_map(const struct rc5_clock *c,const struct rc5_state *s,uint64_t tick,uint64_t epoch){(void)c;(void)s;(void)tick;(void)epoch;}
void r2_ble_timing_lamps(bool tx,bool correction,uint64_t now){(void)tx;(void)correction;(void)now;}
void r2_ble_lamps(uint8_t out[8],uint64_t now){(void)now;memset(out,0,8);}
void r2_time_precision_snapshot(struct r2_pps_precision_view *out){memset(out,0,sizeof *out);}
int r2_console_note(const char *bytes,size_t size,uint64_t expiry){(void)bytes;(void)size;(void)expiry;return -EAGAIN;}
```
